# LPC15xx register map
File version: 0.7
CPU: CM3 r2p1, little endian, no MPU, no FPU, 3 interrupt priority bits
Registers are 32-bit, read-write, reset 0x0 unless marked. A register's access mark holds for its fields unless they carry their own. Offsets are from the block's base; [hi:lo] are bit positions; {n}, {i} and the like mark numbered series; 'fields as' and 'values as' point back to an identical list.

## QEI — Quadrature Encoder Interface (QEI)
Base 0x40058000
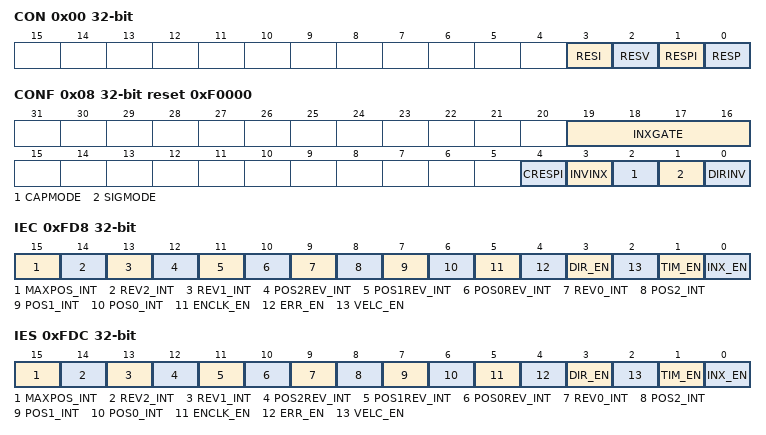
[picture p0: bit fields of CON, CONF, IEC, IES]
0x00 CON wo — Control register
  [3] RESI — Reset index counter. When set = 1, resets the index counter to all zeros. Autoclears when the index counter is cleared.
  [2] RESV — Reset velocity. When set = 1, resets the velocity counter to all zeros and reloads the velocity timer. Autoclears when the velocity counter is cleared.
  [1] RESPI — Reset position counter on index. When set = 1, resets the position counter to all zeros when an index pulse occurs. Autoclears when the position counter is cleared.
  [0] RESP — Reset position counter. When set = 1, resets the position counter to all zeros. Autoclears when the position counter is cleared.
0x04 STAT ro — Encoder status register
  [0] DIR — Direction bit. In combination with DIRINV bit indicates forward or reverse direction. See Table 284.
0x08 CONF reset 0xF0000 — Configuration register
  [19:16] INXGATE — Index gating configuration: when INXGATE(19)=1, pass the index when Pha=0 and Phb=0, else block. when INXGATE(18)=1, pass the index when Pha=0 and Phb=1, else block. when INXGATE(17)=1, pass the index when Pha=1 and Phb=1, else block. when INXGATE(16)=1, pass the index when Pha=1 and Phb=0, else block.
  [4] CRESPI — Continuously reset position counter on index. When set = 1, resets the position counter to all zeros when an index pulse occurs at the next position increase (recalibration). Auto-clears when the position counter is cleared.
  [3] INVINX — Invert Index. When set, inverts the sense of the index input.
  [2] CAPMODE — Capture Mode. When = 0, only PhA edges are counted (2X). When = 1, BOTH PhA and PhB edges are counted (4X), increasing resolution but decreasing range.
  [1] SIGMODE — Signal Mode. When = 0, PhA and PhB function as quadrature encoder inputs. When = 1, PhA functions as the direction signal and PhB functions as the clock signal.
  [0] DIRINV — Direction invert. When = 1, complements the DIR bit.
0x0C POS ro — Position register
  [31:0] POS — Current position value.
0x10 MAXPOS — Maximum position register
  [31:0] MAXPOS — Maximum position value.
{0x14+4i} CMPOS{i} reset 0xFFFFFFFF (i=0..2) — position compare register {i}
  [31:0] PCMP{i} — Position compare value {i}.
0x20 INXCNT ro — Index count register
  [31:0] ENCPOS — Current encoder position value.
0x24 INXCMP0 reset 0xFFFFFFFF — Index compare register 0
  [31:0] ICMP0 — Index compare value.
0x28 LOAD reset 0xFFFFFFFF — Velocity timer reload register
  [31:0] VELLOAD — Current velocity timer pre-load value.The velocity timer counts down from this value.
0x2C TIME ro reset 0xFFFFFFFF — Velocity timer register
  [31:0] VELVAL — Current velocity timer value.
0x30 VEL ro — Velocity counter register
  [31:0] VELPC — Current velocity pulse count.
0x34 CAP ro reset 0xFFFFFFFF — Velocity capture register
  [31:0] VELCAP — Velocity capture value.
0x38 VELCOMP — Velocity compare register
  [31:0] VELCMP — Velocity compare value.
0x3C FILTERPHA — Digital filter register on input phase A (QEI_A)
  [31:0] FILTA — Digital filter sampling delay
0x40 FILTERPHB — Digital filter register on input phase B (QEI_B)
  [31:0] FILTB — Digital filter sampling delay
0x44 FILTERINX — Digital filter register on input index (QEI_IDX)
  [31:0] FITLINX — Digital filter sampling delay
0x48 WINDOW — Index acceptance window register
  [31:0] WINDOW — Index acceptance window width
0x4C INXCMP1 reset 0xFFFFFFFF — Index compare register 1
  [31:0] ICMP1 — Index compare value 1.
0x50 INXCMP2 reset 0xFFFFFFFF — Index compare register 2
  [31:0] ICMP2 — Index compare value 2.
0xFD8 IEC wo — Interrupt enable clear register
  [15] MAXPOS_INT — Indicates that the current position count goes through the MAXPOS value to zero in forward direction, or through zero to MAXPOS in backward direction.
  [14] REV2_INT — Indicates that the index 2 compare value is equal to the current index count.
  [13] REV1_INT — Indicates that the index 1 compare value is equal to the current index count.
  [12] POS2REV_INT — Combined position 2 and revolution count interrupt. Set when both the POS2_INT bit is set and the REV2_INT is set.
  [11] POS1REV_INT — Combined position 1 and revolution count interrupt. Set when both the POS1_INT bit is set and the REV1_INT is set.
  [10] POS0REV_INT — Combined position 0 and revolution count interrupt. Set when both the POS0_INT bit is set and the REV0_Int is set.
  [9] REV0_INT — Indicates that the index 0 compare value is equal to the current index count.
  [8] POS2_INT — Indicates that the position 2 compare value is equal to the current position.
  [7] POS1_INT — Indicates that the position 1compare value is equal to the current position.
  [6] POS0_INT — Indicates that the position 0 compare value is equal to the current position.
  [5] ENCLK_EN — Indicates that and encoder clock pulse was detected.
  [4] ERR_EN — Indicates that an encoder phase error was detected.
  [3] DIR_EN — Indicates that a change of direction was detected.
  [2] VELC_EN — Indicates that captured velocity is less than compare velocity.
  [1] TIM_EN — Indicates that a velocity timer overflow occurred
  [0] INX_EN — Indicates that an index pulse was detected.
0xFDC IES wo — Interrupt enable set register
  [15] MAXPOS_INT — Indicates that the current position count goes through the MAXPOS value to zero in forward direction, or through zero to MAXPOS in backward direction.
  [14] REV2_INT — Indicates that the index 2 compare value is equal to the current index count.
  [13] REV1_INT — Indicates that the index 1 compare value is equal to the current index count.
  [12] POS2REV_INT — Combined position 2 and revolution count interrupt. Set when both the POS2_INT bit is set and the REV2_INT is set.
  [11] POS1REV_INT — Combined position 1 and revolution count interrupt. Set when both the POS1_INT bit is set and the REV1_INT is set.
  [10] POS0REV_INT — Combined position 0 and revolution count interrupt. Set when both the POS0_INT bit is set and the REV0_INT is set.
  [9] REV0_INT — Indicates that the index compare value is equal to the current index count.
  [8] POS2_INT — Indicates that the position 2 compare value is equal to the current position.
  [7] POS1_INT — Indicates that the position 1 compare value is equal to the current position.
  [6] POS0_INT — Indicates that the position 0 compare value is equal to the current position.
  [5] ENCLK_EN — Indicates that and encoder clock pulse was detected.
  [4] ERR_EN — Indicates that an encoder phase error was detected.
  [3] DIR_EN — Indicates that a change of direction was detected.
  [2] VELC_EN — Indicates that captured velocity is less than compare velocity.
  [1] TIM_EN — Indicates that a velocity timer overflow occurred
  [0] INX_EN — Indicates that an index pulse was detected.
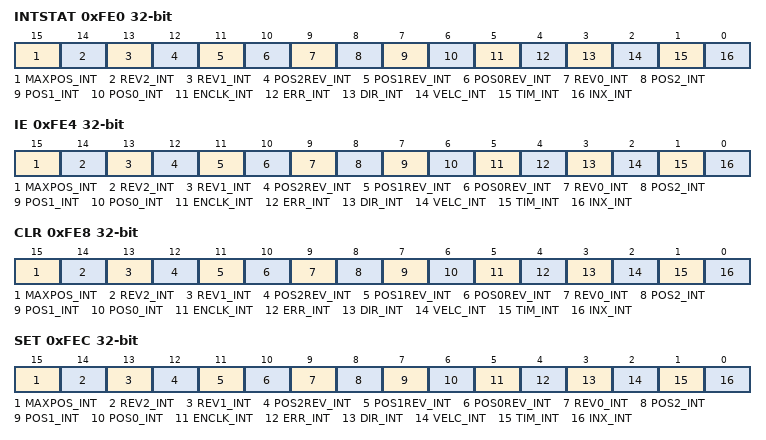
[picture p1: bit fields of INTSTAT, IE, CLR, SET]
0xFE0 INTSTAT ro — Interrupt status register
  [15] MAXPOS_INT — Indicates that the current position count goes through the MAXPOS value to zero in forward direction, or through zero to MAXPOS in backward direction.
  [14] REV2_INT — Indicates that the index 2 compare value is equal to the current index count.
  [13] REV1_INT — Indicates that the index 1 compare value is equal to the current index count.
  [12] POS2REV_INT — Combined position 2 and revolution count interrupt. Set when both the POS2_INT bit is set and the REV2_INT is set.
  [11] POS1REV_INT — Combined position 1 and revolution count interrupt. Set when both the POS1_INT bit is set and the REV1_INT is set.
  [10] POS0REV_INT — Combined position 0 and revolution count interrupt. Set when both the POS0_INT bit is set and the REV0_INT is set.
  [9] REV0_INT — Indicates that the index compare value is equal to the current index count.
  [8] POS2_INT — Indicates that the position 2 compare value is equal to the current position.
  [7] POS1_INT — Indicates that the position 1compare value is equal to the current position.
  [6] POS0_INT — Indicates that the position 0 compare value is equal to the current position.
  [5] ENCLK_INT — Indicates that and encoder clock pulse was detected.
  [4] ERR_INT — Indicates that an encoder phase error was detected.
  [3] DIR_INT — Indicates that a change of direction was detected.
  [2] VELC_INT — Indicates that captured velocity is less than compare velocity.
  [1] TIM_INT — Indicates that a velocity timer overflow occurred
  [0] INX_INT — Indicates that an index pulse was detected.
0xFE4 IE wo — Interrupt enable clear register
  fields as INTSTAT
0xFE8 CLR wo — Interrupt status clear register
  fields as INTSTAT
0xFEC SET wo — Interrupt status set register
  fields as INTSTAT
